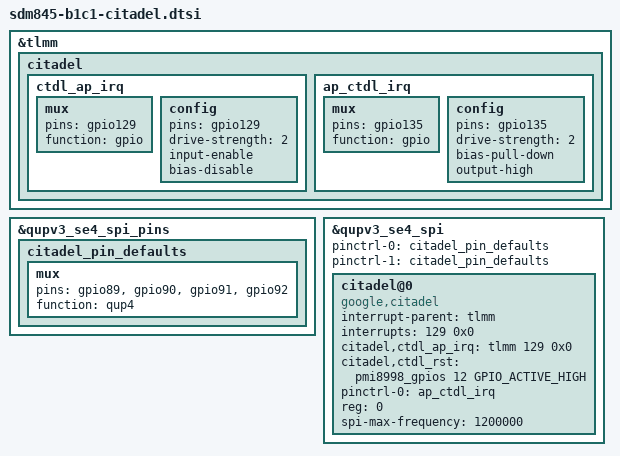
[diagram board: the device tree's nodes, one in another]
/* Copyright (c) 2017, The Linux Foundation. All rights reserved.
 *
 * This program is free software; you can redistribute it and/or modify
 * it under the terms of the GNU General Public License version 2 and
 * only version 2 as published by the Free Software Foundation.
 *
 * This program is distributed in the hope that it will be useful,
 * but WITHOUT ANY WARRANTY; without even the implied warranty of
 * MERCHANTABILITY or FITNESS FOR A PARTICULAR PURPOSE.  See the
 * GNU General Public License for more details.
 */

&tlmm {
	citadel {
		ctdl_ap_irq: ctdl_ap_irq {
			mux {
				pins = "gpio129";
				function = "gpio";
			};

			config {
				pins = "gpio129";
				drive-strength = <2>; /* 2 MA */
				input-enable;
				bias-disable;
			};
		};

		ap_ctdl_irq: ap_ctdl_irq {
			mux {
				pins = "gpio135";
				function = "gpio";
			};

			config {
				pins = "gpio135";
				drive-strength = <2>; /* 2 MA */
				bias-pull-down;
				output-high;
			};
		};
	};
};

&qupv3_se4_spi_pins {
	citadel_pin_defaults: citadel_pin_defaults {
		mux {
			pins = "gpio89", "gpio90", "gpio91", "gpio92";
			function = "qup4";
		};
	};
};

&qupv3_se4_spi {
	status = "okay";
	pinctrl-0 = <&citadel_pin_defaults>;
	pinctrl-1 = <&citadel_pin_defaults>;
	citadel@0 {
		compatible = "google,citadel";
		interrupt-parent = <&tlmm>;
		interrupts = <129 0x0>;
		citadel,ctdl_ap_irq = <&tlmm 129 0x0>;
		citadel,ctdl_rst = <&pmi8998_gpios 12 GPIO_ACTIVE_HIGH>;
		pinctrl-names = "ap_ctdl_irq";
		pinctrl-0 = <&ap_ctdl_irq>;
		reg = <0>;
		spi-max-frequency = <1200000>;
	};
};
